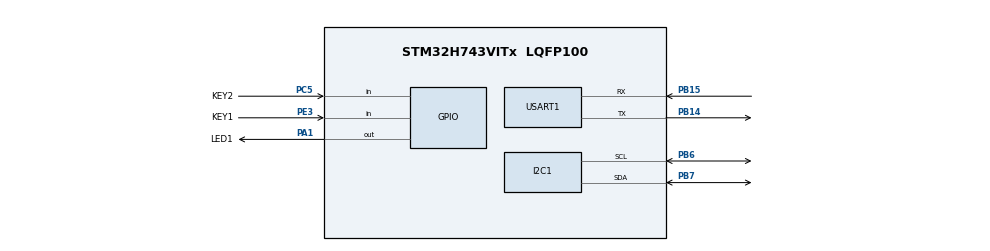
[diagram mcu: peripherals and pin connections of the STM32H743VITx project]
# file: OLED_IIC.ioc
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Dma.I2C1_TX.1.Direction=DMA_MEMORY_TO_PERIPH
Dma.I2C1_TX.1.EventEnable=DISABLE
Dma.I2C1_TX.1.FIFOMode=DMA_FIFOMODE_DISABLE
Dma.I2C1_TX.1.Instance=DMA1_Stream1
Dma.I2C1_TX.1.MemDataAlignment=DMA_MDATAALIGN_BYTE
Dma.I2C1_TX.1.MemInc=DMA_MINC_ENABLE
Dma.I2C1_TX.1.Mode=DMA_NORMAL
Dma.I2C1_TX.1.PeriphDataAlignment=DMA_PDATAALIGN_BYTE
Dma.I2C1_TX.1.PeriphInc=DMA_PINC_DISABLE
Dma.I2C1_TX.1.Polarity=HAL_DMAMUX_REQ_GEN_RISING
Dma.I2C1_TX.1.Priority=DMA_PRIORITY_LOW
Dma.I2C1_TX.1.RequestNumber=1
Dma.I2C1_TX.1.SignalID=NONE
Dma.I2C1_TX.1.SyncEnable=DISABLE
Dma.I2C1_TX.1.SyncPolarity=HAL_DMAMUX_SYNC_NO_EVENT
Dma.I2C1_TX.1.SyncRequestNumber=1
Dma.I2C1_TX.1.SyncSignalID=NONE
Dma.Request0=USART1_RX
Dma.Request1=I2C1_TX
Dma.USART1_RX.0.Direction=DMA_PERIPH_TO_MEMORY
Dma.USART1_RX.0.EventEnable=DISABLE
Dma.USART1_RX.0.FIFOMode=DMA_FIFOMODE_DISABLE
Dma.USART1_RX.0.Instance=DMA1_Stream0
Dma.USART1_RX.0.MemDataAlignment=DMA_MDATAALIGN_BYTE
Dma.USART1_RX.0.MemInc=DMA_MINC_ENABLE
Dma.USART1_RX.0.Mode=DMA_NORMAL
Dma.USART1_RX.0.PeriphDataAlignment=DMA_PDATAALIGN_BYTE
Dma.USART1_RX.0.PeriphInc=DMA_PINC_DISABLE
Dma.USART1_RX.0.Polarity=HAL_DMAMUX_REQ_GEN_RISING
Dma.USART1_RX.0.Priority=DMA_PRIORITY_LOW
Dma.USART1_RX.0.RequestNumber=1
Dma.USART1_RX.0.SignalID=NONE
Dma.USART1_RX.0.SyncEnable=DISABLE
Dma.USART1_RX.0.SyncPolarity=HAL_DMAMUX_SYNC_NO_EVENT
Dma.USART1_RX.0.SyncRequestNumber=1
Dma.USART1_RX.0.SyncSignalID=NONE
I2C1.Timing=0x10C0ECFF
Mcu.Family=STM32H7
Mcu.Name=STM32H743VITx
Mcu.Package=LQFP100
NVIC.DMA1_Stream0_IRQn=true\:0\:0\:false\:false\:true\:false\:true\:true
NVIC.DMA1_Stream1_IRQn=true\:0\:0\:false\:false\:true\:false\:true\:true
NVIC.I2C1_EV_IRQn=true\:0\:0\:false\:false\:true\:true\:true\:true
NVIC.PriorityGroup=NVIC_PRIORITYGROUP_4
PA1.GPIO_Label=LED1
PA1.Signal=GPIO_Output
PA13\ (JTMS/SWDIO).Mode=Serial_Wire
PA13\ (JTMS/SWDIO).Signal=DEBUG_JTMS-SWDIO
PA14\ (JTCK/SWCLK).Mode=Serial_Wire
PA14\ (JTCK/SWCLK).Signal=DEBUG_JTCK-SWCLK
PB14.Mode=Asynchronous
PB14.Signal=USART1_TX
PB15.Mode=Asynchronous
PB15.Signal=USART1_RX
PB6.Mode=I2C
PB6.Signal=I2C1_SCL
PB7.Mode=I2C
PB7.Signal=I2C1_SDA
PC5.GPIO_Label=KEY2
PC5.GPIO_PuPd=GPIO_PULLUP
PC5.Signal=GPIO_Input
PE3.GPIO_Label=KEY1
PE3.GPIO_PuPd=GPIO_PULLUP
PE3.Signal=GPIO_Input
PH0-OSC_IN\ (PH0).Mode=HSE-External-Oscillator
PH0-OSC_IN\ (PH0).Signal=RCC_OSC_IN
PH1-OSC_OUT\ (PH1).Mode=HSE-External-Oscillator
PH1-OSC_OUT\ (PH1).Signal=RCC_OSC_OUT
ProjectManager.HeapSize=0x200
ProjectManager.StackSize=0x400
ProjectManager.TargetToolchain=STM32CubeIDE
RCC.ADCFreq_Value=50390625
RCC.APB1Freq_Value=100000000
RCC.APB2Freq_Value=100000000
RCC.APB3Freq_Value=100000000
RCC.APB4Freq_Value=100000000
RCC.CortexFreq_Value=400000000
RCC.D1PPRE=RCC_APB3_DIV2
RCC.D2PPRE1=RCC_APB1_DIV2
RCC.D2PPRE2=RCC_APB2_DIV2
RCC.D3PPRE=RCC_APB4_DIV2
RCC.DIVM1=2
RCC.DIVN1=64
RCC.HCLKFreq_Value=200000000
RCC.HPRE=RCC_HCLK_DIV2
RCC.PLLSourceVirtual=RCC_PLLSOURCE_HSE
RCC.ProductRev=revV
RCC.SYSCLKFreq_VALUE=400000000
RCC.SYSCLKSource=RCC_SYSCLKSOURCE_PLLCLK
RCC.USBFreq_Value=400000000
USART1.VirtualMode-Asynchronous=VM_ASYNC
board=custom

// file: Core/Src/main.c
/* USER CODE BEGIN Header */
/**
  ******************************************************************************
  * @file           : main.c
  * @brief          : Main program body
  ******************************************************************************
  * @attention
  *
  * Copyright (c) 2023 STMicroelectronics.
  * All rights reserved.
  *
  * This software is licensed under terms that can be found in the LICENSE file
  * in the root directory of this software component.
  * If no LICENSE file comes with this software, it is provided AS-IS.
  *
  ******************************************************************************
  */
/* USER CODE END Header */
#include "main.h"

/* USER CODE BEGIN Includes */
#include "retarget.h"
/* USER CODE END Includes */

I2C_HandleTypeDef hi2c1;
DMA_HandleTypeDef hdma_i2c1_tx;

UART_HandleTypeDef huart1;
DMA_HandleTypeDef hdma_usart1_rx;

void SystemClock_Config(void);

static void MX_GPIO_Init(void);

static void MX_DMA_Init(void);

static void MX_I2C1_Init(void);

static void MX_USART1_UART_Init(void);

int main(void) {

    /* MCU Configuration--------------------------------------------------------*/

    /* Reset of all peripherals, Initializes the Flash interface and the Systick. */
    HAL_Init();

    /* Configure the system clock */
    SystemClock_Config();

    /* Initialize all configured peripherals */
    MX_GPIO_Init();
    MX_DMA_Init();
    MX_I2C1_Init();
    MX_USART1_UART_Init();
    /* USER CODE BEGIN 2 */
    OLED_init();
    /* USER CODE END 2 */

    /* Infinite loop */
    /* USER CODE BEGIN WHILE */
//    animateLineDemo1();
//    HAL_Delay(1000);

    animatePointDemo2();
    HAL_Delay(1000);

    animatePseudo3DDemo();
    HAL_Delay(1000);

    animateStringDemo();
    HAL_Delay(1000);

    animateBallAnimation(30, 10);
    HAL_Delay(1000);

    OLED_display_off();
    //TODO: 暂时无法实现滚动
//    OLED_scrollStop();
//    OLED_scrollingSetup(OLED_CMD_SCROLL_H_RIGHT, 0x00, 0x07, 0x07);
//    OLED_scrollStart();

    while (1) {
        HAL_GPIO_TogglePin(LED1_GPIO_Port, LED1_Pin);
        HAL_Delay(500);
        /* USER CODE END WHILE */

    }
}

void SystemClock_Config(void) {
    RCC_OscInitTypeDef RCC_OscInitStruct = {0};
    RCC_ClkInitTypeDef RCC_ClkInitStruct = {0};

    /** Supply configuration update enable
    */
    HAL_PWREx_ConfigSupply(PWR_LDO_SUPPLY);

    /** Configure the main internal regulator output voltage
    */
    __HAL_PWR_VOLTAGESCALING_CONFIG(PWR_REGULATOR_VOLTAGE_SCALE1);

    while (!__HAL_PWR_GET_FLAG(PWR_FLAG_VOSRDY)) {}

    /** Initializes the RCC Oscillators according to the specified parameters
    * in the RCC_OscInitTypeDef structure.
    */
    RCC_OscInitStruct.OscillatorType = RCC_OSCILLATORTYPE_HSE;
    RCC_OscInitStruct.HSEState = RCC_HSE_ON;
    RCC_OscInitStruct.PLL.PLLState = RCC_PLL_ON;
    RCC_OscInitStruct.PLL.PLLSource = RCC_PLLSOURCE_HSE;
    RCC_OscInitStruct.PLL.PLLM = 2;
    RCC_OscInitStruct.PLL.PLLN = 64;
    RCC_OscInitStruct.PLL.PLLP = 2;
    RCC_OscInitStruct.PLL.PLLQ = 2;
    RCC_OscInitStruct.PLL.PLLR = 2;
    RCC_OscInitStruct.PLL.PLLRGE = RCC_PLL1VCIRANGE_3;
    RCC_OscInitStruct.PLL.PLLVCOSEL = RCC_PLL1VCOWIDE;
    RCC_OscInitStruct.PLL.PLLFRACN = 0;
    if (HAL_RCC_OscConfig(&RCC_OscInitStruct) != HAL_OK) {
        Error_Handler();
    }

    /** Initializes the CPU, AHB and APB buses clocks
    */
    RCC_ClkInitStruct.ClockType = RCC_CLOCKTYPE_HCLK | RCC_CLOCKTYPE_SYSCLK
                                  | RCC_CLOCKTYPE_PCLK1 | RCC_CLOCKTYPE_PCLK2
                                  | RCC_CLOCKTYPE_D3PCLK1 | RCC_CLOCKTYPE_D1PCLK1;
    RCC_ClkInitStruct.SYSCLKSource = RCC_SYSCLKSOURCE_PLLCLK;
    RCC_ClkInitStruct.SYSCLKDivider = RCC_SYSCLK_DIV1;
    RCC_ClkInitStruct.AHBCLKDivider = RCC_HCLK_DIV2;
    RCC_ClkInitStruct.APB3CLKDivider = RCC_APB3_DIV2;
    RCC_ClkInitStruct.APB1CLKDivider = RCC_APB1_DIV2;
    RCC_ClkInitStruct.APB2CLKDivider = RCC_APB2_DIV2;
    RCC_ClkInitStruct.APB4CLKDivider = RCC_APB4_DIV2;

    if (HAL_RCC_ClockConfig(&RCC_ClkInitStruct, FLASH_LATENCY_2) != HAL_OK) {
        Error_Handler();
    }
}

static void MX_I2C1_Init(void) {

    hi2c1.Instance = I2C1;
    hi2c1.Init.Timing = 0x10C0ECFF;
    hi2c1.Init.OwnAddress1 = 0;
    hi2c1.Init.AddressingMode = I2C_ADDRESSINGMODE_7BIT;
    hi2c1.Init.DualAddressMode = I2C_DUALADDRESS_DISABLE;
    hi2c1.Init.OwnAddress2 = 0;
    hi2c1.Init.OwnAddress2Masks = I2C_OA2_NOMASK;
    hi2c1.Init.GeneralCallMode = I2C_GENERALCALL_DISABLE;
    hi2c1.Init.NoStretchMode = I2C_NOSTRETCH_DISABLE;
    if (HAL_I2C_Init(&hi2c1) != HAL_OK) {
        Error_Handler();
    }

    /** Configure Analogue filter
    */
    if (HAL_I2CEx_ConfigAnalogFilter(&hi2c1, I2C_ANALOGFILTER_ENABLE) != HAL_OK) {
        Error_Handler();
    }

    /** Configure Digital filter
    */
    if (HAL_I2CEx_ConfigDigitalFilter(&hi2c1, 0) != HAL_OK) {
        Error_Handler();
    }

}

static void MX_USART1_UART_Init(void) {

    huart1.Instance = USART1;
    huart1.Init.BaudRate = 115200;
    huart1.Init.WordLength = UART_WORDLENGTH_8B;
    huart1.Init.StopBits = UART_STOPBITS_1;
    huart1.Init.Parity = UART_PARITY_NONE;
    huart1.Init.Mode = UART_MODE_TX_RX;
    huart1.Init.HwFlowCtl = UART_HWCONTROL_NONE;
    huart1.Init.OverSampling = UART_OVERSAMPLING_16;
    huart1.Init.OneBitSampling = UART_ONE_BIT_SAMPLE_DISABLE;
    huart1.Init.ClockPrescaler = UART_PRESCALER_DIV1;
    huart1.AdvancedInit.AdvFeatureInit = UART_ADVFEATURE_NO_INIT;
    if (HAL_UART_Init(&huart1) != HAL_OK) {
        Error_Handler();
    }
    if (HAL_UARTEx_SetTxFifoThreshold(&huart1, UART_TXFIFO_THRESHOLD_1_8) != HAL_OK) {
        Error_Handler();
    }
    if (HAL_UARTEx_SetRxFifoThreshold(&huart1, UART_RXFIFO_THRESHOLD_1_8) != HAL_OK) {
        Error_Handler();
    }
    if (HAL_UARTEx_DisableFifoMode(&huart1) != HAL_OK) {
        Error_Handler();
    }

}

static void MX_DMA_Init(void) {

    /* DMA controller clock enable */
    __HAL_RCC_DMA1_CLK_ENABLE();

    /* DMA interrupt init */
    /* DMA1_Stream0_IRQn interrupt configuration */
    HAL_NVIC_SetPriority(DMA1_Stream0_IRQn, 0, 0);
    HAL_NVIC_EnableIRQ(DMA1_Stream0_IRQn);
    /* DMA1_Stream1_IRQn interrupt configuration */
    HAL_NVIC_SetPriority(DMA1_Stream1_IRQn, 0, 0);
    HAL_NVIC_EnableIRQ(DMA1_Stream1_IRQn);

}

static void MX_GPIO_Init(void) {
    GPIO_InitTypeDef GPIO_InitStruct = {0};

    /* GPIO Ports Clock Enable */
    __HAL_RCC_GPIOE_CLK_ENABLE();
    __HAL_RCC_GPIOH_CLK_ENABLE();
    __HAL_RCC_GPIOA_CLK_ENABLE();
    __HAL_RCC_GPIOC_CLK_ENABLE();
    __HAL_RCC_GPIOB_CLK_ENABLE();

    /*Configure GPIO pin Output Level */
    HAL_GPIO_WritePin(LED1_GPIO_Port, LED1_Pin, GPIO_PIN_RESET);

    /*Configure GPIO pin : KEY1_Pin */
    GPIO_InitStruct.Pin = KEY1_Pin;
    GPIO_InitStruct.Mode = GPIO_MODE_INPUT;
    GPIO_InitStruct.Pull = GPIO_PULLUP;
    HAL_GPIO_Init(KEY1_GPIO_Port, &GPIO_InitStruct);

    /*Configure GPIO pin : LED1_Pin */
    GPIO_InitStruct.Pin = LED1_Pin;
    GPIO_InitStruct.Mode = GPIO_MODE_OUTPUT_PP;
    GPIO_InitStruct.Pull = GPIO_NOPULL;
    GPIO_InitStruct.Speed = GPIO_SPEED_FREQ_LOW;
    HAL_GPIO_Init(LED1_GPIO_Port, &GPIO_InitStruct);

    /*Configure GPIO pin : KEY2_Pin */
    GPIO_InitStruct.Pin = KEY2_Pin;
    GPIO_InitStruct.Mode = GPIO_MODE_INPUT;
    GPIO_InitStruct.Pull = GPIO_PULLUP;
    HAL_GPIO_Init(KEY2_GPIO_Port, &GPIO_InitStruct);

}

void Error_Handler(void) {
    __disable_irq();
    while (1) {
    }
}
